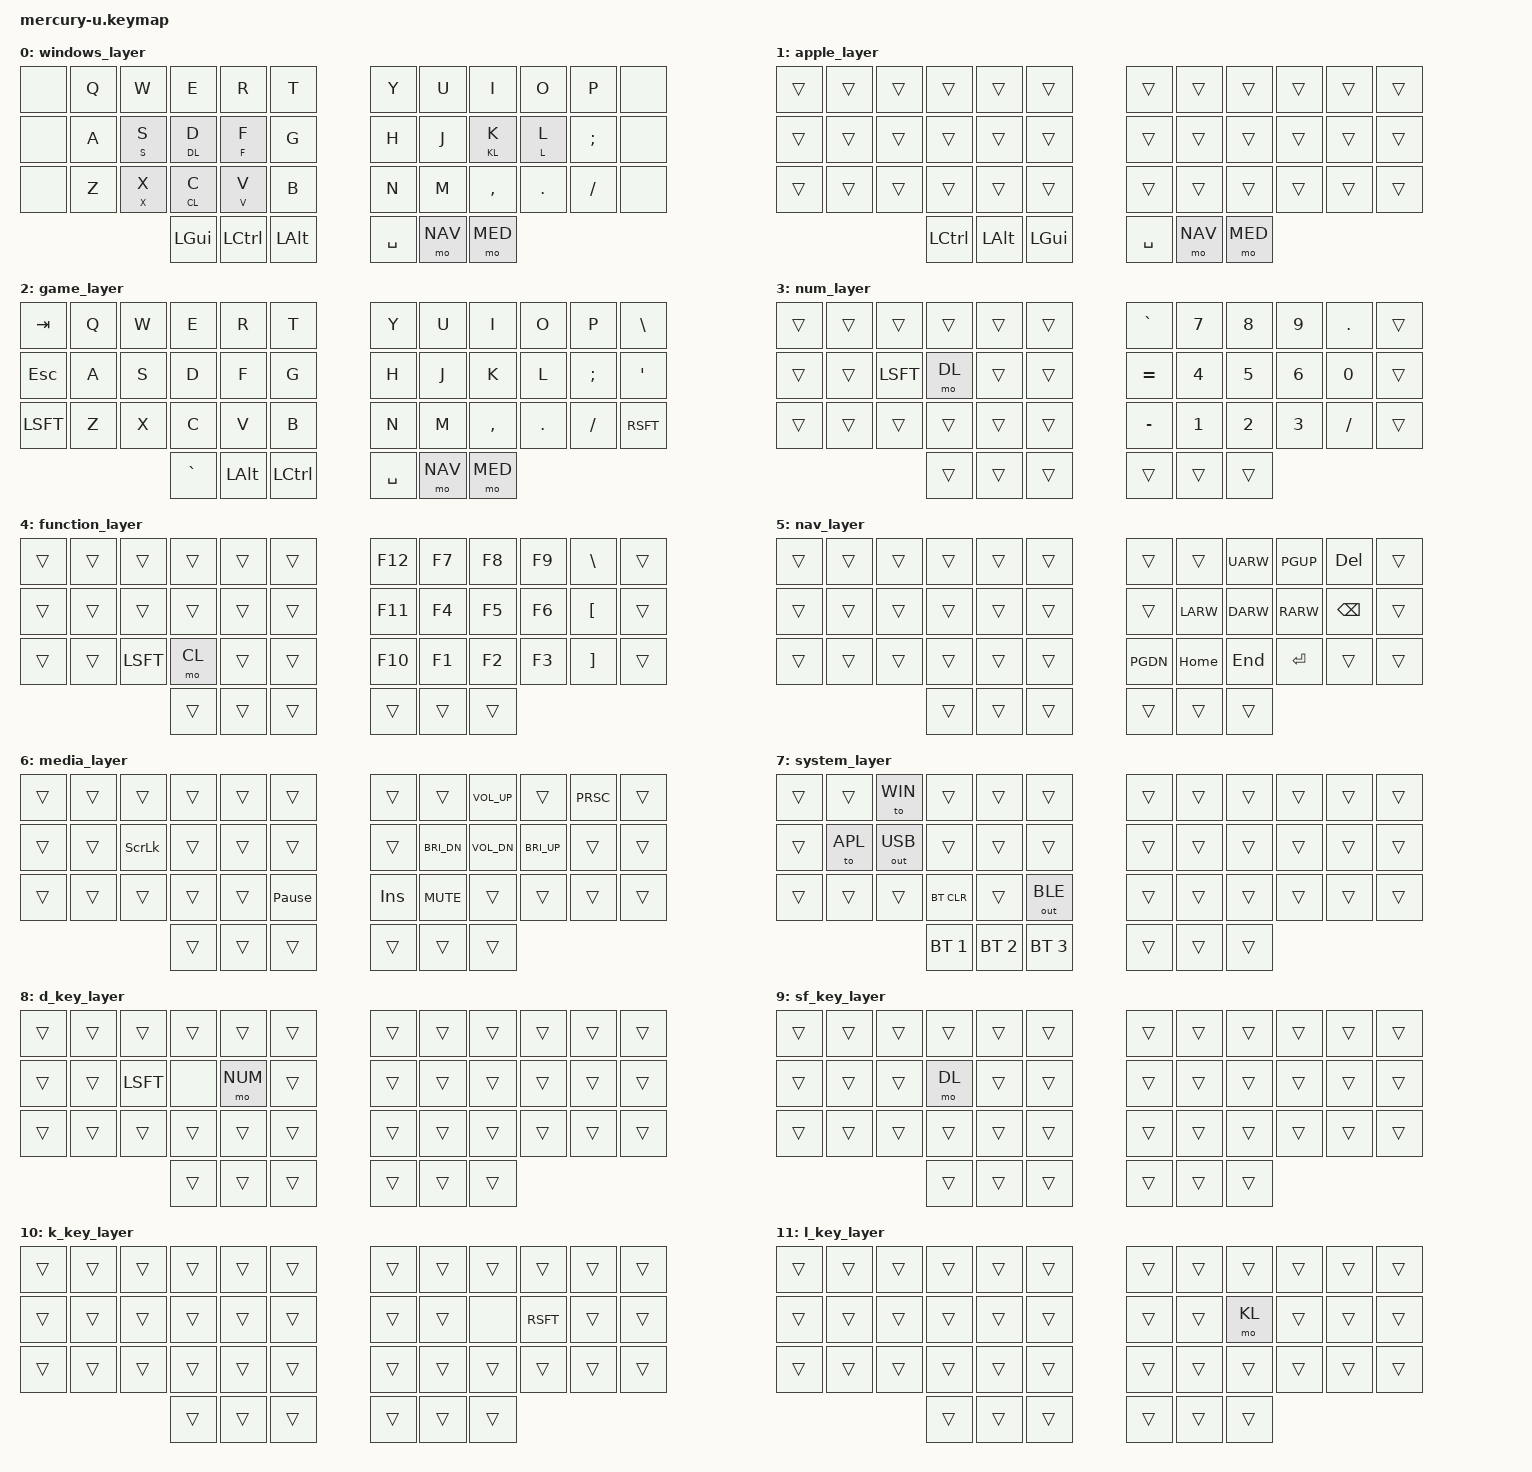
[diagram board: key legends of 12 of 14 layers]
#include <behaviors.dtsi>
#include <dt-bindings/zmk/bt.h>
#include <dt-bindings/zmk/keys.h>
#include <dt-bindings/zmk/outputs.h>

// Layers ENUM
#define WIN 0     // Windows
#define APL 1     // Apple
#define GAM 2     // Gaming
#define NUM 3     // Numbers
#define FUN 4     // Function (F-keys)
#define NAV 5     // Navigation
#define MED 6     // Media
#define SYS 7     // System
#define DL  8     // D-Layer
#define SFL 9     // S/F-Layer
#define KL  10    // K-Layer
#define LL  11    // L-Layer
#define CL  12    // C-Layer
#define XVL 13    // X/V-Layer

// 11Jul2022
// still miss the X+C => Tab combo on rare occasions, increase timeout from 75 to 100
// Sometimes with words like "talk", the rolled "lk" becomes RShift. Decrease timeout to 50.
// #define FAST_COMBO_TIMEOUT 50
// #define MED_COMBO_TIMEOUT 75
// #define SLOW_COMBO_TIMEOUT 100

// 21Jul2022
// I accidentally trigger X+C => Tab combo when typing "Excel". This combo is too sensitive to timing.
// Instead, I'll move Tab combo to R+F, and Esc combo to F+G. Since all of these keys are usually index
// finger only, we can use very long timeouts for them.
// #define RH_COMBO_TIMEOUT 50
// #define LH_COMBO_TIMEOUT 75
// #define SINGLE_FINGER_COMBO_TIMEOUT 150

// 2Jan2023
// The word "sounds" sometimes comes out as "soundSHIFT", so let's decrease timeout from 75 to 50 ms.
// Also, can probably get away with increasing SINGLE_FINGER_COMBO_TIMEOUT from 150 to 200 ms.
#define RH_COMBO_TIMEOUT 50
#define LH_COMBO_TIMEOUT 50
#define SINGLE_FINGER_COMBO_TIMEOUT 200

/ {
    behaviors {};

    macros {
        mcs: macro_s {
            label = "MACRO_S";
            compatible = "zmk,behavior-macro";
            #binding-cells = <0>;
            wait-ms = <0>;
            bindings
                = <&macro_press &mo SFL &kp LSFT>
                , <&macro_pause_for_release>
                , <&macro_release &mo SFL &kp LSFT>
                ;
        };

        mcf: macro_f {
            label = "MACRO_F";
            compatible = "zmk,behavior-macro";
            #binding-cells = <0>;
            wait-ms = <0>;
            bindings
                = <&macro_press &mo SFL &mo NUM>
                , <&macro_pause_for_release>
                , <&macro_release &mo SFL &mo NUM>
                ;
        };

        mcl: macro_l {
            label = "MACRO_L";
            compatible = "zmk,behavior-macro";
            #binding-cells = <0>;
            wait-ms = <0>;
            bindings
                = <&macro_press &mo KL &kp RSFT>
                , <&macro_pause_for_release>
                , <&macro_release &mo KL &kp RSFT>
                ;
        };

        mcx: macro_x {
            label = "MACRO_X";
            compatible = "zmk,behavior-macro";
            #binding-cells = <0>;
            wait-ms = <0>;
            bindings
                = <&macro_press &mo XVL &kp LSFT>
                , <&macro_pause_for_release>
                , <&macro_release &mo XVL &kp LSFT>
                ;
        };

        mcv: macro_v {
            label = "MACRO_V";
            compatible = "zmk,behavior-macro";
            #binding-cells = <0>;
            wait-ms = <0>;
            bindings
                = <&macro_press &mo XVL &mo FUN>
                , <&macro_pause_for_release>
                , <&macro_release &mo XVL &mo FUN>
                ;
        };
    };

    behaviors {
        smt: s_macro_tap {
            compatible = "zmk,behavior-hold-tap";
            label = "S_MACRO_TAP";
            #binding-cells = <2>;
            flavor = "tap-unless-interrupted";
            tapping-term-ms = <LH_COMBO_TIMEOUT>;
            bindings = <&mcs>, <&kp>;
            hold-trigger-key-positions = <15 16 36 37 38 40 41>;
        };

        dlt: d_layer_tap {
            compatible = "zmk,behavior-hold-tap";
            label = "D_LAYER_TAP";
            #binding-cells = <2>;
            flavor = "tap-unless-interrupted";
            tapping-term-ms = <LH_COMBO_TIMEOUT>;
            bindings = <&mo>, <&kp>;
            hold-trigger-key-positions = <14 16 36 37 38 40 41>;
        };

        fmt: f_macro_tap {
            compatible = "zmk,behavior-hold-tap";
            label = "F_MACRO_TAP";
            #binding-cells = <2>;
            flavor = "tap-unless-interrupted";
            tapping-term-ms = <LH_COMBO_TIMEOUT>;
            bindings = <&mcf>, <&kp>;
            hold-trigger-key-positions = <14 15 36 37 38 40 41>;
        };

        klt: k_layer_tap {
            compatible = "zmk,behavior-hold-tap";
            label = "K_LAYER_TAP";
            #binding-cells = <2>;
            flavor = "tap-unless-interrupted";
            tapping-term-ms = <RH_COMBO_TIMEOUT>;
            bindings = <&mo>, <&kp>;
            hold-trigger-key-positions = <21 36 37 38 40 41>;
        };
        
        lmt: l_macro_tap {
            compatible = "zmk,behavior-hold-tap";
            label = "L_MACRO_TAP";
            #binding-cells = <2>;
            flavor = "tap-unless-interrupted";
            tapping-term-ms = <RH_COMBO_TIMEOUT>;
            bindings = <&mcl>, <&kp>;
            hold-trigger-key-positions = <20 36 37 38 40 41>;
        };

        xmt: x_macro_tap {
            compatible = "zmk,behavior-hold-tap";
            label = "X_MACRO_TAP";
            #binding-cells = <2>;
            flavor = "tap-unless-interrupted";
            tapping-term-ms = <LH_COMBO_TIMEOUT>;
            bindings = <&mcx>, <&kp>;
            hold-trigger-key-positions = <27 28 36 37 38 40 41>;
        };

        clt: c_layer_tap {
            compatible = "zmk,behavior-hold-tap";
            label = "C_LAYER_TAP";
            #binding-cells = <2>;
            flavor = "tap-unless-interrupted";
            tapping-term-ms = <LH_COMBO_TIMEOUT>;
            bindings = <&mo>, <&kp>;
            hold-trigger-key-positions = <26 28 36 37 38 40 41>;
        };

        vmt: v_macro_tap {
            compatible = "zmk,behavior-hold-tap";
            label = "V_MACRO_TAP";
            #binding-cells = <2>;
            flavor = "tap-unless-interrupted";
            tapping-term-ms = <LH_COMBO_TIMEOUT>;
            bindings = <&mcv>, <&kp>;
            hold-trigger-key-positions = <26 27 36 37 38 40 41>;
        };
    };

    sl {
        release-after-ms = <20000>; // 20 seconds
    };

    combos {
        compatible = "zmk,combos";

        combo_sys {
            timeout-ms = <LH_COMBO_TIMEOUT>;
            key-positions = <1 2 3>;
            bindings = <&sl SYS>;
        };
        combo_standard {
            timeout-ms = <LH_COMBO_TIMEOUT>;
            key-positions = <13 14 15>;
            bindings = <&to WIN>;
        };
        combo_game {
            timeout-ms = <LH_COMBO_TIMEOUT>;
            key-positions = <25 26 27>;
            bindings = <&to GAM>;
        };

        // Slow combos: these combos exclusively use keys controlled by a single index-finger,
        // which makes them very unlikely to be accidentally triggered by a standard touch-typist
        // them during normal typing, even with a very long timeout.
        combo_tab {
            timeout-ms = <SINGLE_FINGER_COMBO_TIMEOUT>;
            key-positions = <4 17>;
            bindings = <&kp TAB>;
        };
        combo_esc {
            timeout-ms = <SINGLE_FINGER_COMBO_TIMEOUT>;
            key-positions = <16 17>;
            bindings = <&kp ESC>;
        };
        combo_quote {
            timeout-ms = <RH_COMBO_TIMEOUT>;
            key-positions = <19 20>;
            bindings = <&kp QUOT>;
        };
        combo_caps {
            timeout-ms = <SINGLE_FINGER_COMBO_TIMEOUT>;
            key-positions = <30 31>;
            bindings = <&kp CAPS>;
        };
        combo_fwd_slash {
            timeout-ms = <SINGLE_FINGER_COMBO_TIMEOUT>;
            key-positions = <7 18>; /* HU */
            bindings = <&kp FSLH>;
        };
        combo_menu {
            timeout-ms = <SINGLE_FINGER_COMBO_TIMEOUT>;
            key-positions = <18 19>; /* HJ */
            bindings = <&kp K_CMENU>;
        };
    };

    keymap {
        compatible = "zmk,keymap";

        windows_layer {
            bindings = <
&none  &kp Q  &kp W     &kp E      &kp R     &kp T     /**/  &kp Y    &kp U    &kp I      &kp O     &kp P     &none
&none  &kp A  &smt S S  &dlt DL D  &fmt F F  &kp G     /**/  &kp H    &kp J    &klt KL K  &lmt L L  &kp SCLN  &none
&none  &kp Z  &xmt X X  &clt CL C  &vmt V V  &kp B     /**/  &kp N    &kp M    &kp CMMA   &kp DOT   &kp FSLH  &none
                        &kp LGUI   &kp LCTL  &kp LALT  /**/  &kp SPC  &mo NAV  &mo MED
            >;
        };
        
        apple_layer {
            bindings = <
&trans  &trans  &trans  &trans    &trans    &trans    /**/  &trans   &trans   &trans   &trans  &trans  &trans
&trans  &trans  &trans  &trans    &trans    &trans    /**/  &trans   &trans   &trans   &trans  &trans  &trans
&trans  &trans  &trans  &trans    &trans    &trans    /**/  &trans   &trans   &trans   &trans  &trans  &trans
                        &kp LCTL  &kp LALT  &kp LGUI  /**/  &kp SPC  &mo NAV  &mo MED
            >;
        };

        game_layer {
            bindings = <
&kp TAB   &kp Q  &kp W  &kp E     &kp R     &kp T     /**/  &kp Y    &kp U    &kp I     &kp O    &kp P     &kp BSLH
&kp ESC   &kp A  &kp S  &kp D     &kp F     &kp G     /**/  &kp H    &kp J    &kp K     &kp L    &kp SCLN  &kp QUOT
&kp LSFT  &kp Z  &kp X  &kp C     &kp V     &kp B     /**/  &kp N    &kp M    &kp CMMA  &kp DOT  &kp FSLH  &kp RSFT
                        &kp GRAV  &kp LALT  &kp LCTL  /**/  &kp SPC  &mo NAV  &mo MED
            >;
        };

        num_layer {
            bindings = <
&trans  &trans  &trans    &trans  &trans  &trans  /**/  &kp GRAV   &kp N7  &kp N8  &kp N9  &kp DOT   &trans
&trans  &trans  &kp LSFT  &mo DL  &trans  &trans  /**/  &kp EQL    &kp N4  &kp N5  &kp N6  &kp N0    &trans
&trans  &trans  &trans    &trans  &trans  &trans  /**/  &kp MINUS  &kp N1  &kp N2  &kp N3  &kp FSLH  &trans
                          &trans  &trans  &trans  /**/  &trans     &trans  &trans
            >;
        };

        function_layer {
            bindings = <
&trans  &trans  &trans    &trans  &trans   &trans  /**/  &kp F12  &kp F7  &kp F8  &kp F9  &kp BSLH  &trans
&trans  &trans  &trans    &trans  &trans   &trans  /**/  &kp F11  &kp F4  &kp F5  &kp F6  &kp LBKT  &trans
&trans  &trans  &kp LSFT  &mo CL  &trans   &trans  /**/  &kp F10  &kp F1  &kp F2  &kp F3  &kp RBKT  &trans
                          &trans  &trans   &trans  /**/  &trans   &trans  &trans
            >;
        };

        nav_layer {
            bindings = <
&trans  &trans  &trans  &trans  &trans  &trans  /**/  &trans    &trans    &kp UARW  &kp PGUP  &kp DEL   &trans
&trans  &trans  &trans  &trans  &trans  &trans  /**/  &trans    &kp LARW  &kp DARW  &kp RARW  &kp BKSP  &trans
&trans  &trans  &trans  &trans  &trans  &trans  /**/  &kp PGDN  &kp HOME  &kp END   &kp RET   &trans    &trans
                        &trans  &trans  &trans  /**/  &trans    &trans    &trans
            >;
        };

        media_layer {
            bindings = <
&trans  &trans  &trans    &trans  &trans  &trans           /**/  &trans   &trans        &kp C_VOL_UP  &trans            &kp PRSC    &trans
&trans  &trans  &kp SLCK  &trans  &trans  &trans           /**/  &trans   &kp C_BRI_DN  &kp C_VOL_DN  &kp C_BRI_UP      &trans      &trans
&trans  &trans  &trans    &trans  &trans  &kp PAUSE_BREAK  /**/  &kp INS  &kp C_MUTE    &trans        &trans            &trans      &trans
                          &trans  &trans  &trans           /**/  &trans   &trans        &trans
            >;
        };

        system_layer {
            bindings = <
&trans  &trans   &to WIN       &trans        &trans        &trans        /**/  &trans  &trans  &trans  &trans  &trans  &trans
&trans  &to APL  &out OUT_USB  &trans        &trans        &trans        /**/  &trans  &trans  &trans  &trans  &trans  &trans
&trans  &trans   &trans        &bt BT_CLR    &trans        &out OUT_BLE  /**/  &trans  &trans  &trans  &trans  &trans  &trans
                               &bt BT_SEL 1  &bt BT_SEL 2  &bt BT_SEL 3  /**/  &trans  &trans  &trans
            >;
        };

        d_key_layer {
            bindings = <
&trans  &trans  &trans    &trans  &trans   &trans  /**/  &trans  &trans  &trans  &trans  &trans  &trans
&trans  &trans  &kp LSFT  &none   &mo NUM  &trans  /**/  &trans  &trans  &trans  &trans  &trans  &trans
&trans  &trans  &trans    &trans  &trans   &trans  /**/  &trans  &trans  &trans  &trans  &trans  &trans
                          &trans  &trans   &trans  /**/  &trans  &trans  &trans
            >;
        };

        sf_key_layer {
            bindings = <
&trans  &trans  &trans  &trans  &trans   &trans  /**/  &trans  &trans  &trans  &trans  &trans  &trans
&trans  &trans  &trans  &mo DL  &trans   &trans  /**/  &trans  &trans  &trans  &trans  &trans  &trans
&trans  &trans  &trans  &trans  &trans   &trans  /**/  &trans  &trans  &trans  &trans  &trans  &trans
                        &trans  &trans   &trans  /**/  &trans  &trans  &trans
            >;
        };

        k_key_layer {
            bindings = <
&trans  &trans  &trans  &trans  &trans  &trans  /**/  &trans  &trans  &trans  &trans    &trans  &trans
&trans  &trans  &trans  &trans  &trans  &trans  /**/  &trans  &trans  &none   &kp RSFT  &trans  &trans
&trans  &trans  &trans  &trans  &trans  &trans  /**/  &trans  &trans  &trans  &trans    &trans  &trans
                        &trans  &trans  &trans  /**/  &trans  &trans  &trans
            >;
        };

        l_key_layer {
            bindings = <
&trans  &trans  &trans  &trans  &trans   &trans  /**/  &trans  &trans  &trans  &trans  &trans  &trans
&trans  &trans  &trans  &trans  &trans   &trans  /**/  &trans  &trans  &mo KL  &trans  &trans  &trans
&trans  &trans  &trans  &trans  &trans   &trans  /**/  &trans  &trans  &trans  &trans  &trans  &trans
                        &trans  &trans   &trans  /**/  &trans  &trans  &trans
            >;
        };

        c_key_layer {
            bindings = <
&trans  &trans  &trans    &trans  &trans   &trans  /**/  &trans  &trans  &trans  &trans  &trans  &trans
&trans  &trans  &trans    &trans  &trans   &trans  /**/  &trans  &trans  &trans  &trans  &trans  &trans
&trans  &trans  &kp LSFT  &none   &mo FUN  &trans  /**/  &trans  &trans  &trans  &trans  &trans  &trans
                          &trans  &trans   &trans  /**/  &trans  &trans  &trans
            >;
        };

        xv_key_layer {
            bindings = <
&trans  &trans  &trans  &trans  &trans  &trans  /**/  &trans  &trans  &trans  &trans  &trans  &trans
&trans  &trans  &trans  &trans  &trans  &trans  /**/  &trans  &trans  &trans  &trans  &trans  &trans
&trans  &trans  &trans  &mo CL  &trans  &trans  /**/  &trans  &trans  &trans  &trans  &trans  &trans
                        &trans  &trans  &trans  /**/  &trans  &trans  &trans
            >;
        };
    };
};
